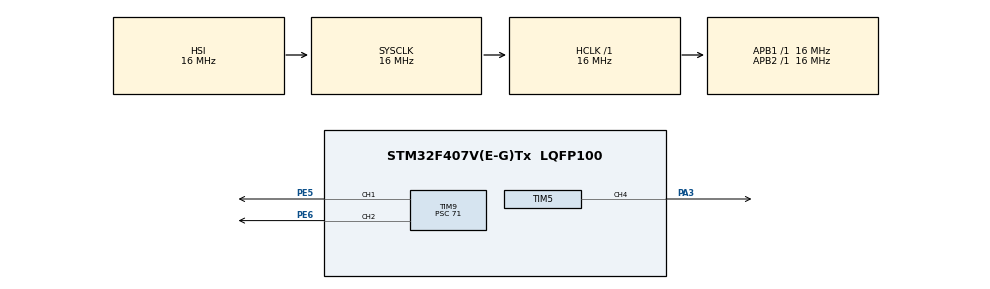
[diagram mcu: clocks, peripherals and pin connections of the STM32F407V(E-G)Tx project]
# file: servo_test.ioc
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Mcu.Family=STM32F4
Mcu.Name=STM32F407V(E-G)Tx
Mcu.Package=LQFP100
NVIC.PriorityGroup=NVIC_PRIORITYGROUP_4
NVIC.TIM1_BRK_TIM9_IRQn=true\:0\:0\:false\:false\:true\:true\:true\:true
PA3.Signal=S_TIM5_CH4
PE5.Signal=S_TIM9_CH1
PE6.Signal=S_TIM9_CH2
ProjectManager.HeapSize=0x200
ProjectManager.StackSize=0x400
ProjectManager.TargetToolchain=STM32CubeIDE
RCC.AHBFreq_Value=16000000
RCC.APB1Freq_Value=16000000
RCC.APB2Freq_Value=16000000
RCC.CortexFreq_Value=16000000
RCC.HSE_VALUE=25000000
RCC.HSI_VALUE=16000000
RCC.LSE_VALUE=32768
RCC.SYSCLKFreq_VALUE=16000000
RCC.VCOOutputFreq_Value=192000000
SH.S_TIM5_CH4.0=TIM5_CH4,PWM Generation4 CH4
SH.S_TIM9_CH1.0=TIM9_CH1,PWM Generation1 CH1
SH.S_TIM9_CH2.0=TIM9_CH2,PWM Generation2 CH2
TIM5.Channel-PWM\ Generation4\ CH4=TIM_CHANNEL_4
TIM9.Channel-PWM\ Generation1\ CH1=TIM_CHANNEL_1
TIM9.Channel-PWM\ Generation2\ CH2=TIM_CHANNEL_2
TIM9.Period=19999
TIM9.Prescaler=71
TIM9.Pulse-PWM\ Generation1\ CH1=1500
TIM9.Pulse-PWM\ Generation2\ CH2=2000
board=custom

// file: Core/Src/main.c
/* USER CODE BEGIN Header */
/**
  ******************************************************************************
  * @file           : main.c
  * @brief          : Main program body
  ******************************************************************************
  * @attention
  *
  * Copyright (c) 2025 STMicroelectronics.
  * All rights reserved.
  *
  * This software is licensed under terms that can be found in the LICENSE file
  * in the root directory of this software component.
  * If no LICENSE file comes with this software, it is provided AS-IS.
  *
  ******************************************************************************
  */
/* USER CODE END Header */
#include "main.h"

TIM_HandleTypeDef htim5;
TIM_HandleTypeDef htim9;

void SystemClock_Config(void);
static void MX_GPIO_Init(void);
static void MX_TIM5_Init(void);
static void MX_TIM9_Init(void);
/* USER CODE BEGIN PFP */
void set_servo_angle(TIM_HandleTypeDef *htim, uint32_t channel, uint8_t angle);
/* USER CODE END PFP */

int main(void)
{

  /* MCU Configuration--------------------------------------------------------*/

  /* Reset of all peripherals, Initializes the Flash interface and the Systick. */
  HAL_Init();

  /* Configure the system clock */
  SystemClock_Config();

  /* Initialize all configured peripherals */
  MX_GPIO_Init();
  MX_TIM5_Init();
  MX_TIM9_Init();
  /* USER CODE BEGIN 2 */
  HAL_TIM_PWM_Start(&htim9, TIM_CHANNEL_1);
    HAL_TIM_PWM_Start(&htim9, TIM_CHANNEL_2);
  /* USER CODE END 2 */

  /* Infinite loop */
  /* USER CODE BEGIN WHILE */
  while (1)
  {
	  for (uint8_t angle = 0; angle <= 180; angle += 10)
	    {
	      set_servo_angle(&htim9, TIM_CHANNEL_1, angle);
	      set_servo_angle(&htim9, TIM_CHANNEL_2, 180 - angle);
	      HAL_Delay(500);
	    }
    /* USER CODE END WHILE */

  }
}

void SystemClock_Config(void)
{
  RCC_OscInitTypeDef RCC_OscInitStruct = {0};
  RCC_ClkInitTypeDef RCC_ClkInitStruct = {0};

  /** Configure the main internal regulator output voltage
  */
  __HAL_RCC_PWR_CLK_ENABLE();
  __HAL_PWR_VOLTAGESCALING_CONFIG(PWR_REGULATOR_VOLTAGE_SCALE1);

  /** Initializes the RCC Oscillators according to the specified parameters
  * in the RCC_OscInitTypeDef structure.
  */
  RCC_OscInitStruct.OscillatorType = RCC_OSCILLATORTYPE_HSI;
  RCC_OscInitStruct.HSIState = RCC_HSI_ON;
  RCC_OscInitStruct.HSICalibrationValue = RCC_HSICALIBRATION_DEFAULT;
  RCC_OscInitStruct.PLL.PLLState = RCC_PLL_NONE;
  if (HAL_RCC_OscConfig(&RCC_OscInitStruct) != HAL_OK)
  {
    Error_Handler();
  }

  /** Initializes the CPU, AHB and APB buses clocks
  */
  RCC_ClkInitStruct.ClockType = RCC_CLOCKTYPE_HCLK|RCC_CLOCKTYPE_SYSCLK
                              |RCC_CLOCKTYPE_PCLK1|RCC_CLOCKTYPE_PCLK2;
  RCC_ClkInitStruct.SYSCLKSource = RCC_SYSCLKSOURCE_HSI;
  RCC_ClkInitStruct.AHBCLKDivider = RCC_SYSCLK_DIV1;
  RCC_ClkInitStruct.APB1CLKDivider = RCC_HCLK_DIV1;
  RCC_ClkInitStruct.APB2CLKDivider = RCC_HCLK_DIV1;

  if (HAL_RCC_ClockConfig(&RCC_ClkInitStruct, FLASH_LATENCY_0) != HAL_OK)
  {
    Error_Handler();
  }
}

static void MX_TIM5_Init(void)
{

  TIM_MasterConfigTypeDef sMasterConfig = {0};
  TIM_OC_InitTypeDef sConfigOC = {0};

  htim5.Instance = TIM5;
  htim5.Init.Prescaler = 0;
  htim5.Init.CounterMode = TIM_COUNTERMODE_UP;
  htim5.Init.Period = 4294967295;
  htim5.Init.ClockDivision = TIM_CLOCKDIVISION_DIV1;
  htim5.Init.AutoReloadPreload = TIM_AUTORELOAD_PRELOAD_DISABLE;
  if (HAL_TIM_PWM_Init(&htim5) != HAL_OK)
  {
    Error_Handler();
  }
  sMasterConfig.MasterOutputTrigger = TIM_TRGO_RESET;
  sMasterConfig.MasterSlaveMode = TIM_MASTERSLAVEMODE_DISABLE;
  if (HAL_TIMEx_MasterConfigSynchronization(&htim5, &sMasterConfig) != HAL_OK)
  {
    Error_Handler();
  }
  sConfigOC.OCMode = TIM_OCMODE_PWM1;
  sConfigOC.Pulse = 0;
  sConfigOC.OCPolarity = TIM_OCPOLARITY_HIGH;
  sConfigOC.OCFastMode = TIM_OCFAST_DISABLE;
  if (HAL_TIM_PWM_ConfigChannel(&htim5, &sConfigOC, TIM_CHANNEL_4) != HAL_OK)
  {
    Error_Handler();
  }
  HAL_TIM_MspPostInit(&htim5);

}

static void MX_TIM9_Init(void)
{

  TIM_OC_InitTypeDef sConfigOC = {0};

  htim9.Instance = TIM9;
  htim9.Init.Prescaler = 71;
  htim9.Init.CounterMode = TIM_COUNTERMODE_UP;
  htim9.Init.Period = 19999;
  htim9.Init.ClockDivision = TIM_CLOCKDIVISION_DIV1;
  htim9.Init.AutoReloadPreload = TIM_AUTORELOAD_PRELOAD_DISABLE;
  if (HAL_TIM_PWM_Init(&htim9) != HAL_OK)
  {
    Error_Handler();
  }
  sConfigOC.OCMode = TIM_OCMODE_PWM1;
  sConfigOC.Pulse = 1500;
  sConfigOC.OCPolarity = TIM_OCPOLARITY_HIGH;
  sConfigOC.OCFastMode = TIM_OCFAST_DISABLE;
  if (HAL_TIM_PWM_ConfigChannel(&htim9, &sConfigOC, TIM_CHANNEL_1) != HAL_OK)
  {
    Error_Handler();
  }
  sConfigOC.Pulse = 0;
  if (HAL_TIM_PWM_ConfigChannel(&htim9, &sConfigOC, TIM_CHANNEL_2) != HAL_OK)
  {
    Error_Handler();
  }
  HAL_TIM_MspPostInit(&htim9);

}

static void MX_GPIO_Init(void)
{

  /* GPIO Ports Clock Enable */
  __HAL_RCC_GPIOE_CLK_ENABLE();
  __HAL_RCC_GPIOA_CLK_ENABLE();

}

/* USER CODE BEGIN 4 */
void set_servo_angle(TIM_HandleTypeDef *htim, uint32_t channel, uint8_t angle) {
    // angle: 0~180 → pulse width: 1000~2000 us
   uint16_t pulse = 500 + ((uint32_t)angle * 2000) / 180;
    __HAL_TIM_SET_COMPARE(htim, channel, pulse);
}
/* USER CODE END 4 */

void Error_Handler(void)
{
  __disable_irq();
  while (1)
  {
  }
}
